# M55M1 register map
File version: 1.0
Registers are 32-bit, read-write, reset 0x0 unless marked. A register's access mark holds for its fields unless they carry their own. Offsets are from the block's base; [hi:lo] are bit positions; {n}, {i} and the like mark numbered series; 'fields as' and 'values as' point back to an identical list.

## CLK (part 2 of 2) — CLK Register Map
Base 0x40001000
0x25C CLK_I3CCTL — I3C Clock Enable Control Register
  [0] I3C0CKEN — I3Cx Clock Enable Bit. Note: This bit is not retained when D0 power is turned off.
    0=I3Cx clock Disabled; 1=I3Cx clock Enabled
0x260 CLK_KDFCTL — KDF Clock Enable Control Register
  [0] KDF0CKEN — KDFx Clock Enable Bit. Note: This bit is not retained when D0 power is turned off.
    0=KDFx clock Disabled; 1=KDFx clock Enabled
0x264 CLK_KPICTL — KPI Clock Enable Control Register
  [0] KPI0CKEN — KPIx Clock Enable Bit. Note: This bit is not retained when D0 power is turned off.
    0=KPIx clock Disabled; 1=KPIx clock Enabled
0x268 CLK_KSCTL — KS Clock Enable Control Register
  [0] KS0CKEN — KSx Clock Enable Bit. Note: This bit is not retained when D0 power is turned off.
    0=KSx clock Disabled; 1=KSx clock Enabled
0x26C CLK_LPADCCTL — Low Power ADC Clock Enable Control Register
  [0] LPADC0CKEN — LPADCx Clock Enable Bit. Note: This bit is not retained when D0 power is turned off.
    0=LPADCx clock Disabled; 1=LPADCx clock Enabled
0x270 CLK_LPPDMACTL — Low Power PDMA Clock Enable Control Register
  [0] LPPDMA0CKEN — LPPDMAx Clock Enable Bit. Note: This bit is not retained when D0 power is turned off.
    0=LPPDMAx clock Disabled; 1=LPPDMAx clock Enabled
0x274 CLK_LPGPIOCTL — Low Power GPIO Clock Enable Control Register
  [0] LPGPIO0CKEN — LPGPIOx Clock Enable Bit. Note: This bit is not retained when D0 power is turned off.
    0=LPGPIOx clock Disabled; 1=LPGPIOx clock Enabled
0x278 CLK_LPI2CCTL — Low Power I2C Clock Enable Control Register
  [0] LPI2C0CKEN — LPI2Cx Clock Enable Bit. Note: This bit is not retained when D0 power is turned off.
    0=LPI2Cx clock Disabled; 1=LPI2Cx clock Enabled
0x27C CLK_LPSPICTL — Low Power SPI Clock Enable Control Register
  [0] LPSPI0CKEN — LPSPIx Clock Enable Bit. Note: This bit is not retained when D0 power is turned off.
    0=LPSPIx clock Disabled; 1=LPSPIx clock Enabled
0x280 CLK_LPSRAMCTL — Low Power SRAM Clock Enable Control Register
  [0] LPSRAM0CKEN — LPSRAMx Clock Enable Bit. Note: This bit is not retained when D0 power is turned off.
    0=LPSRAMx clock Disabled; 1=LPSRAMx clock Enabled
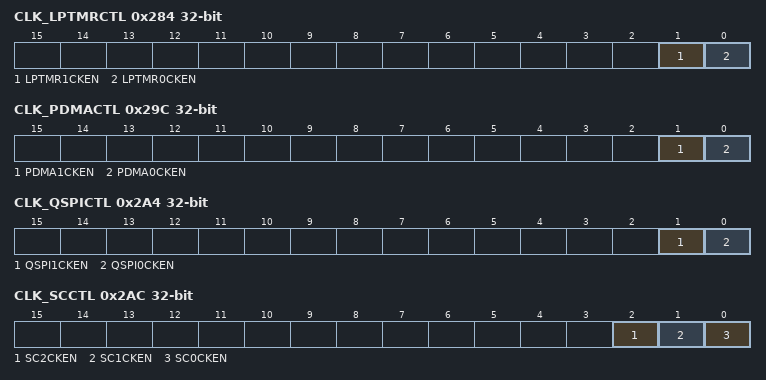
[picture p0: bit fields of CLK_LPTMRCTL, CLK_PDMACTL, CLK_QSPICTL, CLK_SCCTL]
0x284 CLK_LPTMRCTL — Low Power Timer Clock Enable Control Register
  [1] LPTMR1CKEN — LPTMRx Clock Enable Bit. Note: This bit is not retained when D0 power is turned off.
    0=LPTMRx clock Disabled; 1=LPTMRx clock Enabled
  [0] LPTMR0CKEN — LPTMRx Clock Enable Bit. Note: This bit is not retained when D0 power is turned off.
    0=LPTMRx clock Disabled; 1=LPTMRx clock Enabled
0x288 CLK_LPUARTCTL — Low Power UART Clock Enable Control Register
  [0] LPUART0CKEN — LPUARTx Clock Enable Bit. Note: This bit is not retained when D0 power is turned off.
    0=LPUARTx clock Disabled; 1=LPUARTx clock Enabled
0x28C CLK_NPUCTL — NPU Clock Enable Control Register
  [0] NPU0CKEN — NPUx Clock Enable Bit. Note: This bit is not retained when D0 power is turned off.
    0=NPUx clock Disabled; 1=NPUx clock Enabled
0x294 CLK_OTFCCTL — OTFC Clock Enable Control Register
  [0] OTFC0CKEN — OTFCx Clock Enable Bit. Note: This bit is not retained when D0 power is turned off.
    0=OTFCx clock Disabled; 1=OTFCx clock Enabled
0x298 CLK_OTGCTL — OTG Clock Enable Control Register
  [0] OTG0CKEN — OTGx Clock Enable Bit. Note: This bit is not retained when D0 power is turned off.
    0=OTGx clock Disabled; 1=OTGx clock Enabled
0x29C CLK_PDMACTL — PDMA Clock Enable Control Register
  [1] PDMA1CKEN — PDMAx Clock Enable Bit. Note: This bit is not retained when D0 power is turned off.
    0=PDMAx clock Disabled; 1=PDMAx clock Enabled
  [0] PDMA0CKEN — PDMAx Clock Enable Bit. Note: This bit is not retained when D0 power is turned off.
    0=PDMAx clock Disabled; 1=PDMAx clock Enabled
0x2A0 CLK_PSIOCTL — PSIO Clock Enable Control Register
  [0] PSIO0CKEN — PSIOx Clock Enable Bit. Note: This bit is not retained when D0 power is turned off.
    0=PSIOx clock Disabled; 1=PSIOx clock Enabled
0x2A4 CLK_QSPICTL — QSPI Clock Enable Control Register
  [1] QSPI1CKEN — QSPIx Clock Enable Bit. Note: This bit is not retained when D0 power is turned off.
    0=QSPIx clock Disabled; 1=QSPIx clock Enabled
  [0] QSPI0CKEN — QSPIx Clock Enable Bit. Note: This bit is not retained when D0 power is turned off.
    0=QSPIx clock Disabled; 1=QSPIx clock Enabled
0x2A8 CLK_RTCCTL — RTC Clock Enable Control Register
  [0] RTC0CKEN — RTCx Clock Enable Bit. Note: This bit is not retained when D0 power is turned off.
    0=RTCx clock Disabled; 1=RTCx clock Enabled
0x2AC CLK_SCCTL — SC Clock Enable Control Register
  [all] fields
    0=SCx clock Disabled; 1=SCx clock Enabled
  [2] SC2CKEN — SCx Clock Enable Bit. Note: This bit is not retained when D0 power is turned off.
  [1] SC1CKEN — SCx Clock Enable Bit. Note: This bit is not retained when D0 power is turned off.
  [0] SC0CKEN — SCx Clock Enable Bit. Note: This bit is not retained when D0 power is turned off.
0x2B0 CLK_SCUCTL reset 0x1 — SCU Clock Enable Control Register
  [0] SCU0CKEN — SCUx Clock Enable Bit. Note: This bit is not retained when D0 power is turned off.
    0=SCUx clock Disabled; 1=SCUx clock Enabled
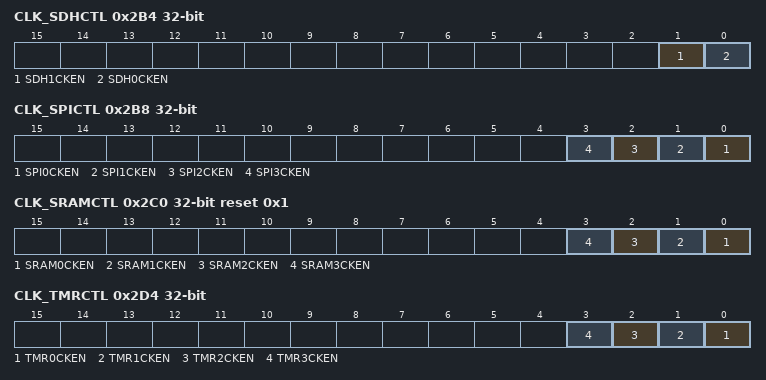
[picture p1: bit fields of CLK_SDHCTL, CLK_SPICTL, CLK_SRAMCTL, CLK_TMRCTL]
0x2B4 CLK_SDHCTL — SDH Clock Enable Control Register
  [1] SDH1CKEN — SDHx Clock Enable Bit. Note: This bit is not retained when D0 power is turned off.
    0=SDHx clock Disabled; 1=SDHx clock Enabled
  [0] SDH0CKEN — SDHx Clock Enable Bit. Note: This bit is not retained when D0 power is turned off.
    0=SDHx clock Disabled; 1=SDHx clock Enabled
0x2B8 CLK_SPICTL — SPI Clock Enable Control Register
  [all] fields
    0=SPIx clock Disabled; 1=SPIx clock Enabled
  [n] SPI{n}CKEN (n=0..3) — SPIx Clock Enable Bit. Note: This bit is not retained when D0 power is turned off.
0x2BC CLK_SPIMCTL — SPIM Clock Enable Control Register
  [0] SPIM0CKEN — SPIMx Clock Enable Bit. Note: This bit is not retained when D0 power is turned off.
    0=SPIMx clock Disabled; 1=SPIMx clock Enabled
0x2C0 CLK_SRAMCTL reset 0x1 — System SRAM Clock Enable Control Register
  [n] SRAM{n}CKEN (n=0..3) — SRAM{n} Clock Enable Bit. Note: This bit is not retained when D0 power is turned off.
    0=SRAM{n} clock Disabled; 1=SRAM{n} clock Enabled
0x2CC CLK_STCTL — System Tick Clock Enable Control Register
  [0] ST0CKEN — SYSTICKx Clock Enable Bit. Note: This bit is not retained when D0 power is turned off.
    0=SYSTICKx clock Disabled; 1=SYSTICKx clock Enabled
0x2D4 CLK_TMRCTL — Timer Clock Enable Control Register
  [all] fields
    0=TIMERx clock Disabled; 1=TIMERx clock Enabled
  [n] TMR{n}CKEN (n=0..3) — TIMERx Clock Enable Bit. Note: This bit is not retained when D0 power is turned off.
0x2D8 CLK_TRNGCTL — TRNG Clock Enable Control Register
  [0] TRNG0CKEN — TRNGx Clock Enable Bit. Note: This bit is not retained when D0 power is turned off.
    0=TRNGx clock Disabled; 1=TRNGx clock Enabled
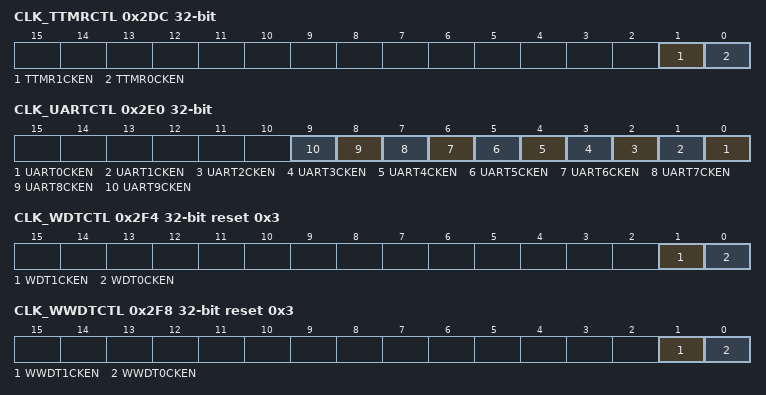
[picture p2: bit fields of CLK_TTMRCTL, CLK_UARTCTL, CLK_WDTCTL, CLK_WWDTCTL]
0x2DC CLK_TTMRCTL — Tick Timer Clock Enable Control Register
  [1] TTMR1CKEN — TTMRx Clock Enable Bit. Note: This bit is not retained when D2 power is turned off.
    0=TTMRx clock Disabled; 1=TTMRx clock Enabled
  [0] TTMR0CKEN — TTMRx Clock Enable Bit. Note: This bit is not retained when D2 power is turned off.
    0=TTMRx clock Disabled; 1=TTMRx clock Enabled
0x2E0 CLK_UARTCTL — UART Clock Enable Control Register
  [all] fields
    0=UARTx clock Disabled; 1=UARTx clock Enabled
  [n] UART{n}CKEN (n=0..9) — UARTx Clock Enable Bit. Note: This bit is not retained when D0 power is turned off.
0x2E4 CLK_USBDCTL — USBD Clock Enable Control Register
  [0] USBD0CKEN — USBDx Clock Enable Bit. Note: This bit is not retained when D0 power is turned off.
    0=USBDx clock Disabled; 1=USBDx clock Enabled
0x2E8 CLK_USBHCTL — USBH Clock Enable Control Register
  [0] USBH0CKEN — USBHx Clock Enable Bit. Note: This bit is not retained when D0 power is turned off.
    0=USBHx clock Disabled; 1=USBHx clock Enabled
0x2EC CLK_USCICTL — USCI Clock Enable Control Register
  [0] USCI0CKEN — USCIx Clock Enable Bit. Note: This bit is not retained when D0 power is turned off.
    0=USCIx clock Disabled; 1=USCIx clock Enabled
0x2F0 CLK_UTCPDCTL — UTCPD Clock Enable Control Register
  [0] UTCPD0CKEN — UTCPDx Clock Enable Bit. Note: This bit is not retained when D0 power is turned off.
    0=UTCPDx clock Disabled; 1=UTCPDx clock Enabled
0x2F4 CLK_WDTCTL reset 0x3 — WDT Clock Enable Control Register
  [1] WDT1CKEN — WDTx Clock Enable Bit. Note 2: This bit is not retained when D2 power is turned off.
    0=WDTx clock Disabled; 1=WDTx clock Enabled
  [0] WDT0CKEN — WDTx Clock Enable Bit. Note 2: This bit is not retained when D2 power is turned off.
    0=WDTx clock Disabled; 1=WDTx clock Enabled
0x2F8 CLK_WWDTCTL reset 0x3 — WWDT Clock Enable Control Register
  [1] WWDT1CKEN — WWDTx Clock Enable Bit. Note 2: This bit is not retained when D0 power is turned off.
    0=WWDTx clock Disabled; 1=WWDTx clock Enabled
  [0] WWDT0CKEN — WWDTx Clock Enable Bit. Note 2: This bit is not retained when D0 power is turned off.
    0=WWDTx clock Disabled; 1=WWDTx clock Enabled
0x400 CLK_SCLKSEL — System Clock Source Select Control Register
  [2:0] SCLKSEL — System Clock Source Selection (Write Protect). The system clock source is defined by SCLKSEL. Note: These bits are write protected. Refer to the SYS_REGLCTL register. Note: These bits are not retained when D2 power is turned off.
    0=Clock source from HIRC; 1=Clock source from MIRC; 2=Clock source from HIRC48M; 3=Clock source from HXT; 4=Clock source from APLL0
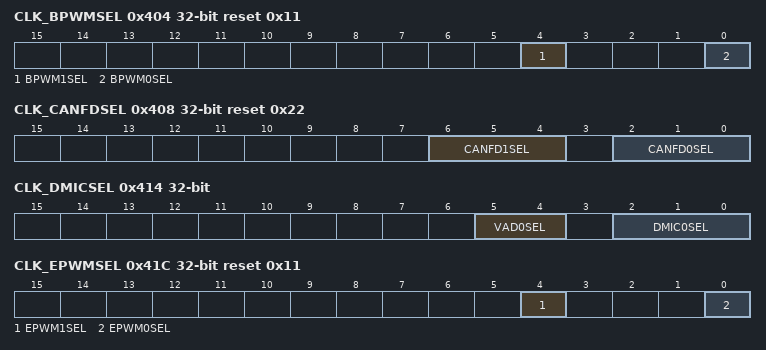
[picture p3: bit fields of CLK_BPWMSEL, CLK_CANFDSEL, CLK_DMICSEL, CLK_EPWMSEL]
0x404 CLK_BPWMSEL reset 0x11 — BPWM Clock Source Select Control Register
  [4] BPWM1SEL — BPWM1 Clock Source Selection (Write Protect). The peripheral clock source of BPWM1 is defined by BPWM1SEL. Note 0: This bit is write protected. Refer to the SYS_REGLCTL register. Note 1: This bit is not retained when D1 power is turned off.
    0=Clock source from PCLK2; 1=Clock source from HCLK0
  [0] BPWM0SEL — BPWM0 Clock Source Selection (Write Protect). The peripheral clock source of BPWM0 is defined by BPWM0SEL. Note 0: This bit is write protected. Refer to the SYS_REGLCTL register. Note 1: This bit is not retained when D1 power is turned off.
    0=Clock source from PCLK0; 1=Clock source from HCLK0
0x408 CLK_CANFDSEL reset 0x22 — CANFD Clock Source Select Control Register
  [6:4] CANFD1SEL — CANFD1 Clock Source Selection (Write Protect). The peripheral clock source of CANFD1 is defined by CANFD1SEL. Note 0: These bits are write protected. Refer to the SYS_REGLCTL register. Note 1: These bits are not retained when D1 power is turned off.
    0=Clock source from HXT; 1=Clock source from APLL0/2; 2=Clock source from HCLK0; 3=Clock source from HIRC; 4=Clock source from HIRC48M/4
  [2:0] CANFD0SEL — CANFD0 Clock Source Selection (Write Protect). The peripheral clock source of CANFD0 is defined by CANFD0SEL. Note 0: These bits are write protected. Refer to the SYS_REGLCTL register. Note 1: These bits are not retained when D1 power is turned off.
    values as CANFD1SEL
0x40C CLK_CCAPSEL reset 0x1 — CCAP Clock Source Select Control Register
  [2:0] CCAP0SEL — CCAP Sensor Clock Source Selection (Write Protect). The peripheral clock source of CCAP is defined by CCAP0SEL. Note 0: These bits are write protected. Refer to the SYS_REGLCTL register. Note 1: These bits are not retained when D2 power is turned off.
    0=Clock source from MIRC; 1=Clock source from HCLK2; 2=Clock source from HIRC; 3=Clock source from APLL0/2; 4=Clock source from HXT
0x410 CLK_CLKOSEL — Clock Output Clock Source Select Control Register
  [3:0] CLKOSEL — Clock Output Clock Source Selection (Write Protect). Note: These bits are write protected. Refer to the SYS_REGLCTL register. Note: These bits are not retained when D2 power is turned off.
    0=Clock source from SCLK; 1=Clock source from ACLK; 2=Clock source from HCLK0; 3=Clock source from HCLK1; 4=Clock source from HCLK2; 5=Clock source from APLL0/2; 6=Clock source from APLL1/2; 7=Clock source from HIRC48M; 8=Clock source from HXT; 9=Clock source from HIRC; 10=Clock source from MIRC; 11=Clock source from LXT; 12=Clock source from LIRC
0x414 CLK_DMICSEL — DMIC Clock Source Select Control Register
  [5:4] VAD0SEL — VAD Clock Source Selection (Write Protect). The peripheral clock VAD source of DIMC0 is defined by VAD0SEL. Note 0: These bits are write protected. Refer to the SYS_REGLCTL register. Note 1: These bits are not retained when D2 power is turned off.
    0=Clock source from PCLK4; 1=Clock source from MIRC; 2=Clock source from HIRC
  [2:0] DMIC0SEL — DMIC Clock Source Selection (Write Protect). The peripheral clock source of DIMC0 is defined by DMIC0SEL. Note 0: These bits are write protected. Refer to the SYS_REGLCTL register. Note 1: These bits are not retained when D2 power is turned off.
    0=Clock source from HXT; 1=Clock source from APLL1/2; 2=Clock source from MIRC; 3=Clock source from HIRC; 4=Clock source from HIRC48M; 5=Clock source from PCLK4
0x418 CLK_EADCSEL reset 0x2 — EADC Clock Source Select Control Register
  [1:0] EADC0SEL — EADC0 Clock Source Selection (Write Protect). The peripheral clock source of EADC0 is defined by EADC0SEL. Note 0: These bits are write protected. Refer to the SYS_REGLCTL register. Note 1: These bits are not retained when D1 power is turned off.
    0=Clock source from APLL1/2; 1=Clock source from APLL0/2; 2=PCLK0
0x41C CLK_EPWMSEL reset 0x11 — EPWM Clock Source Select Control Register
  [4] EPWM1SEL — EPWM1 Clock Source Selection (Write Protect). The peripheral clock source of EPWM1 is defined by EPWM1SEL. Note 0: This bit is write protected. Refer to the SYS_REGLCTL register. Note 1: This bit is not retained when D1 power is turned off.
    0=Clock source from PCLK2; 1=Clock source from HCLK0
  [0] EPWM0SEL — EPWM0 Clock Source Selection (Write Protect). The peripheral clock source of EPWM0 is defined by EPWM0SEL. Note 0: This bit is write protected. Refer to the SYS_REGLCTL register. Note 1: This bit is not retained when D1 power is turned off.
    0=Clock source from PCLK0; 1=Clock source from HCLK0
0x420 CLK_FMCSEL — FMC Clock Source Select Control Register
  [0] FMC0SEL — FMC0 Clock Source Selection (Write Protect). The peripheral clock source of FMC0 is defined by FMC0SEL. Note 0: This bit is write protected. Refer to the SYS_REGLCTL register. Note 1: This bit is not retained when D0 power is turned off.
    0=Clock source from HIRC; 1=Clock source from HIRC48M/4
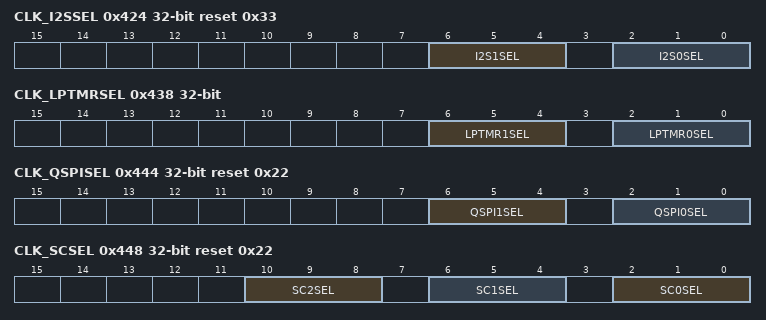
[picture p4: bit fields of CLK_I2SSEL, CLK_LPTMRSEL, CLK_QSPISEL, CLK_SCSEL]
0x424 CLK_I2SSEL reset 0x33 — I2S Clock Source Select Control Register
  [6:4] I2S1SEL — I2S1 Clock Source Selection (Write Protect). The peripheral clock source of I2S1 is defined by I2S1SEL. Note 1: These bits are write protected. Refer to the SYS_REGLCTL register. Note 2: These bits are not retained when D1 power is turned off.
    0=Clock source from HXT; 1=Clock source from APLL1/2; 2=Clock source from APLL0/2; 3=Clock source from PCLK3; 4=Clock source from HIRC; 5=Clock source from HIRC48M
  [2:0] I2S0SEL — I2S0 Clock Source Selection (Write Protect). The peripheral clock source of I2S0 is defined by I2S0SEL. Note 1: These bits are write protected. Refer to the SYS_REGLCTL register. Note 2: These bits are not retained when D1 power is turned off.
    0=Clock source from HXT; 1=Clock source from APLL1/2; 2=Clock source from APLL0/2; 3=Clock source from PCLK1; 4=Clock source from HIRC; 5=Clock source from HIRC48M
0x428 CLK_I3CSEL — I3C Clock Source Select Control Register
  [0] I3C0SEL — I3C0 Clock Source Selection (Write Protect). The peripheral clock source of I3C0 is defined by I3C0SEL. Note 1: This bit is write protected. Refer to the SYS_REGLCTL register. Note 2: This bit is not retained when D1 power is turned off.
    0=Clock source from HCLK0; 1=Clock source from APLL1/2
0x42C CLK_KPISEL — KPI Clock Source Select Control Register
  [1:0] KPI0SEL — KPI0 Clock Source Selection (Write Protect). The peripheral clock source of KPI0 is defined by KPI0SEL. Note 1: These bits are write protected. Refer to the SYS_REGLCTL register. Note 2: These bits are not retained when D1 power is turned off.
    0=Clock source from HIRC48M/4; 1=Clock source from HIRC; 2=Clock source from LIRC; 3=Clock source from HXT
0x430 CLK_LPADCSEL — Low Power ADC Clock Source Select Control Register
  [1:0] LPADC0SEL — LPADC0 Clock Source Selection (Write Protect). The peripheral clock source of LPADC0 is defined by LPADC0SEL. Note 1: These bits are write protected. Refer to the SYS_REGLCTL register. Note 2: These bits are not retained when D2 power is turned off.
    0=Clock source from PCLK4; 1=Clock source from LXT; 2=Clock source from MIRC; 3=Clock source from HIRC
0x434 CLK_LPSPISEL — Low Power SPI Clock Source Select Control Register
  [1:0] LPSPI0SEL — LPSPI0 Clock Source Selection (Write Protect). The peripheral clock source of LPSPI0 is defined by LPSPI0SEL. Note 1: These bits are write protected. Refer to the SYS_REGLCTL register. Note 2: These bits are not retained when D2 power is turned off.
    values as CLK_DMICSEL.VAD0SEL
0x438 CLK_LPTMRSEL — Low Power Timer Clock Source Select Control Register
  [6:4] LPTMR1SEL — LPTMR1 Clock Source Selection (Write Protect). The peripheral clock source of LPTMR1 is defined by LPTMR1SEL. Note 1: These bits are write protected. Refer to the SYS_REGLCTL register. Note 2: These bits are not retained when D2 power is turned off.
    0=Clock source from PCLK4; 1=Clock source from LXT; 2=Clock source from LIRC; 3=Clock source from MIRC; 4=Clock source from HIRC; 5=Clock source from external clock TM1 pin
  [2:0] LPTMR0SEL — LPTMR0 Clock Source Selection (Write Protect). The peripheral clock source of LPTMR0 is defined by LPTMR0SEL. Note 1: These bits are write protected. Refer to the SYS_REGLCTL register. Note 2: These bits are not retained when D2 power is turned off.
    0=Clock source from PCLK4; 1=Clock source from LXT; 2=Clock source from LIRC; 3=Clock source from MIRC; 4=Clock source from HIRC; 5=Clock source from external clock TM0 pin
0x43C CLK_LPUARTSEL — Low Power UART Clock Source Select Control Register
  [1:0] LPUART0SEL — LPUART0 Clock Source Selection (Write Protect). The peripheral clock source of LPUART0 is defined by LPUART0SEL. Note 1: These bits are write protected. Refer to the SYS_REGLCTL register. Note 2: These bits are not retained when D2 power is turned off.
    values as CLK_LPADCSEL.LPADC0SEL
0x440 CLK_PSIOSEL reset 0x5 — PSIO Clock Source Select Control Register
  [2:0] PSIO0SEL — PSIO0 Clock Source Selection (Write Protect). The peripheral clock source of PSIO0 is defined by PSIO0SEL. Note 1: These bits are write protected. Refer to the SYS_REGLCTL register. Note 2: These bits are not retained when D1 power is turned off.
    0=Clock source from LXT; 1=Clock source from HXT; 2=Clock source from LIRC; 3=Clock source from HIRC; 4=Clock source from HIRC48M/4; 5=Clock source from PCLK1; 6=Clock source from APLL0/2
0x444 CLK_QSPISEL reset 0x22 — QSPI Clock Source Select Control Register
  [6:4] QSPI1SEL — QSPI1 Clock Source Selection (Write Protect). The peripheral clock source of QSPI1 is defined by QSPI1SEL. Note 1: These bits are write protected. Refer to the SYS_REGLCTL register. Note 2: These bits are not retained when D1 power is turned off.
    0=Clock source from HXT; 1=Clock source from APLL0/2; 2=Clock source from PCLK2; 3=Clock source from HIRC; 4=Clock source from HIRC48M/4
  [2:0] QSPI0SEL — QSPI0 Clock Source Selection (Write Protect). The peripheral clock source of QSPI0 is defined by QSPI0SEL. Note 1: These bits are write protected. Refer to the SYS_REGLCTL register. Note 2: These bits are not retained when D1 power is turned off.
    0=Clock source from HXT; 1=Clock source from APLL0/2; 2=Clock source from PCLK0; 3=Clock source from HIRC; 4=Clock source from HIRC48M/4
0x448 CLK_SCSEL reset 0x22 — SC Clock Source Select Control Register
  [10:8] SC2SEL — SC2 Clock Source Selection (Write Protect). The peripheral clock source of SC2 is defined by SC2SEL. Note 1: These bits are write protected. Refer to the SYS_REGLCTL register. Note 2: These bits are not retained when D1 power is turned off.
    0=Clock source from HXT; 1=Clock source from APLL0/2; 2=Clock source from PCLK1; 3=Clock source from HIRC; 4=Clock source from HIRC48M/4
  [6:4] SC1SEL — SC1 Clock Source Selection (Write Protect). The peripheral clock source of SC1 is defined by SC1SEL. Note 1: These bits are write protected. Refer to the SYS_REGLCTL register. Note 2: These bits are not retained when D1 power is turned off.
    0=Clock source from HXT; 1=Clock source from APLL0/2; 2=Clock source from PCLK3; 3=Clock source from HIRC; 4=Clock source from HIRC48M/4
  [2:0] SC0SEL — SC0 Clock Source Selection (Write Protect). The peripheral clock source of SC0 is defined by SC0SEL. Note 1: These bits are write protected. Refer to the SYS_REGLCTL register. Note 2: These bits are not retained when D1 power is turned off.
    values as SC2SEL
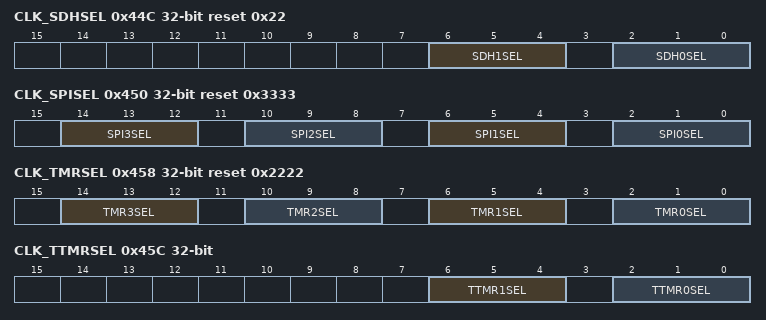
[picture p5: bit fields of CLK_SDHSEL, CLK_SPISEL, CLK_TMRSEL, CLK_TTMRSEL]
0x44C CLK_SDHSEL reset 0x22 — SDH Clock Source Select Control Register
  [6:4] SDH1SEL — SDH1 Clock Source Selection (Write Protect). The peripheral clock source of SDH1 is defined by SDH1SEL. Note 1: These bits are write protected. Refer to the SYS_REGLCTL register. Note 2: These bits are not retained when D1 power is turned off.
    0=Clock source from HXT; 1=Clock source from APLL1/2; 2=Clock source from HCLK0; 3=Clock source from HIRC; 4=Clock source from HIRC48M/4
  [2:0] SDH0SEL — SDH0 Clock Source Selection (Write Protect). The peripheral clock source of SDH0 is defined by SDH0SEL. Note 1: These bits are write protected. Refer to the SYS_REGLCTL register. Note 2: These bits are not retained when D1 power is turned off.
    values as SDH1SEL
0x450 CLK_SPISEL reset 0x3333 — SPI Clock Source Select Control Register
  [14:12] SPI3SEL — SPI3 Clock Source Selection (Write Protect). The peripheral clock source of SPI3 is defined by SPI3SEL. Note 1: These bits are write protected. Refer to the SYS_REGLCTL register. Note 2: These bits are not retained when D1 power is turned off.
    0=Clock source from HXT; 1=Clock source from APLL1/2; 2=Clock source from APLL0/2; 3=Clock source from PCLK2; 4=Clock source from HIRC; 5=Clock source from HIRC48M
  [10:8] SPI2SEL — SPI2 Clock Source Selection (Write Protect). The peripheral clock source of SPI2 is defined by SPI2SEL. Note 1: These bits are write protected. Refer to the SYS_REGLCTL register. Note 2: These bits are not retained when D1 power is turned off.
    0=Clock source from HXT; 1=Clock source from APLL1/2; 2=Clock source from APLL0/2; 3=Clock source from PCLK0; 4=Clock source from HIRC; 5=Clock source from HIRC48M
  [6:4] SPI1SEL — SPI1 Clock Source Selection (Write Protect). The peripheral clock source of SPI1 is defined by SPI1SEL. Note 1: These bits are write protected. Refer to the SYS_REGLCTL register. Note 2: These bits are not retained when D1 power is turned off.
    values as SPI3SEL
  [2:0] SPI0SEL — SPI0 Clock Source Selection (Write Protect). The peripheral clock source of SPI0 is defined by SPI0SEL. Note 1: These bits are write protected. Refer to the SYS_REGLCTL register. Note 2: These bits are not retained when D1 power is turned off.
    values as SPI2SEL
0x454 CLK_STSEL reset 0x2 — System Tick Clock Source Select Control Register
  [1:0] ST0SEL — Cortex-M55 SysTick 0 Clock Source Selection (Write Protect). Note 2: These bits are write protected. Refer to the SYS_REGLCTL register. Note 3: These bits are not retained when D0 power is turned off.
    0=Clock source from HXT; 1=Clock source from HXT/2; 2=Clock source from ACLK/2; 3=Clock source from HIRC/2
0x458 CLK_TMRSEL reset 0x2222 — Timer Clock Source Select Control Register
  [14:12] TMR3SEL — Timer 3 Clock Source Selection (Write Protect). The peripheral clock source of TMR3 is defined by TMR3SEL. Note 1: These bits are write protected. Refer to the SYS_REGLCTL register. Note 2: These bits are not retained when D1 power is turned off.
    0=Clock source from HXT; 1=Clock source from LXT; 2=Clock source from PCLK3; 3=Clock source from external clock TM3 pin; 4=Clock source from LIRC; 5=Clock source from HIRC; 6=Clock source from HIRC48M/4
  [10:8] TMR2SEL — Timer 2 Clock Source Selection (Write Protect). The peripheral clock source of TMR2 is defined by TMR2SEL. Note 1: These bits are write protected. Refer to the SYS_REGLCTL register. Note 2: These bits are not retained when D1 power is turned off.
    0=Clock source from HXT; 1=Clock source from LXT; 2=Clock source from PCLK3; 3=Clock source from external clock TM2 pin; 4=Clock source from LIRC; 5=Clock source from HIRC; 6=Clock source from HIRC48M/4
  [6:4] TMR1SEL — Timer 1 Clock Source Selection (Write Protect). The peripheral clock source of TMR1 is defined by TMR1SEL. Note 1: These bits are write protected. Refer to the SYS_REGLCTL register. Note 2: These bits are not retained when D1 power is turned off.
    0=Clock source from HXT; 1=Clock source from LXT; 2=Clock source from PCLK1; 3=Clock source from external clock TM1 pin; 4=Clock source from LIRC; 5=Clock source from HIRC; 6=Clock source from HIRC48M/4
  [2:0] TMR0SEL — Timer 0 Clock Source Selection (Write Protect). The peripheral clock source of TMR0 is defined by TMR0SEL. Note 1: These bits are write protected. Refer to the SYS_REGLCTL register. Note 2: These bits are not retained when D1 power is turned off.
    0=Clock source from HXT; 1=Clock source from LXT; 2=Clock source from PCLK1; 3=Clock source from external clock TM0 pin; 4=Clock source from LIRC; 5=Clock source from HIRC; 6=Clock source from HIRC48M/4
0x45C CLK_TTMRSEL — Tick Timer Clock Source Select Control Register
  [6:4] TTMR1SEL — Tick Timer 1 Clock Source Selection (Write Protect). The peripheral clock source of TTMR1 is defined by TTMR1SEL. Note 1: These bits are write protected. Refer to the SYS_REGLCTL register. Note 2: These bits are not retained when D2 power is turned off.
    0=Clock source from PCLK4; 1=Clock source from LXT; 2=Clock source from LIRC; 3=Clock source from MIRC; 4=Clock source from HIRC
  [2:0] TTMR0SEL — Tick Timer 0 Clock Source Selection (Write Protect). The peripheral clock source of TTMR0 is defined by TTMR0SEL. Note 1: These bits are write protected. Refer to the SYS_REGLCTL register. Note 2: These bits are not retained when D2 power is turned off.
    values as TTMR1SEL
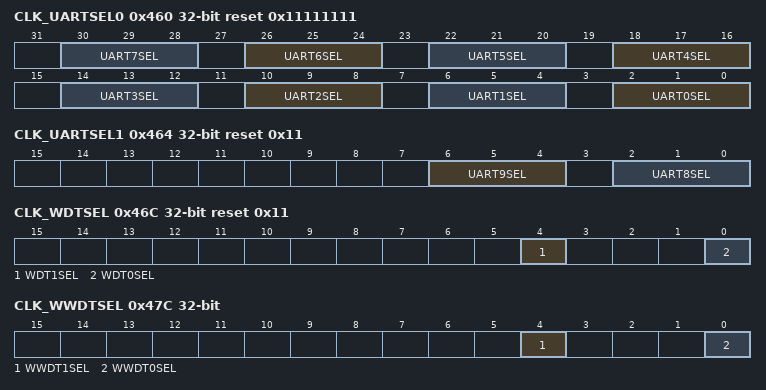
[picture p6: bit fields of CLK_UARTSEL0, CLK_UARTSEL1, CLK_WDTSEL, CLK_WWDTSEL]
0x460 CLK_UARTSEL0 reset 0x11111111 — UART Clock Source Select Control Register 0
  [all] fields
    0=Clock source from HXT; 1=Clock source from HIRC; 2=Clock source from LXT; 3=Clock source from APLL0/2; 4=Clock source from HIRC48M
  [4n+2:4n] UART{n}SEL (n=0..7) — UART {n} Clock Source Selection (Write Protect). The peripheral clock source of UART{n} is defined by UART{n}SEL. Note 1: These bits are write protected. Refer to the SYS_REGLCTL register. Note 2: These bits are not retained when D1 power is turned off.
0x464 CLK_UARTSEL1 reset 0x11 — UART Clock Source Select Control Register 1
  [6:4] UART9SEL — UART 9 Clock Source Selection (Write Protect). The peripheral clock source of UART9 is defined by UART9SEL. Note 1: These bits are write protected. Refer to the SYS_REGLCTL register. Note 2: These bits are not retained when D1 power is turned off.
    values as the fields of CLK_UARTSEL0
  [2:0] UART8SEL — UART 8 Clock Source Selection (Write Protect). The peripheral clock source of UART8 is defined by UART8SEL. Note 1: These bits are write protected. Refer to the SYS_REGLCTL register. Note 2: These bits are not retained when D1 power is turned off.
    values as the fields of CLK_UARTSEL0
0x468 CLK_USBSEL reset 0x1 — USB Clock Source Select Control Register
  [0] USBSEL — USB Clock Source Selection (Write Protect). The peripheral clock source of USBH, USBD and OTG is defined by USBSEL. Note 1: These bits are write protected. Refer to the SYS_REGLCTL register. Note 2: These bits are not retained when D1 power is turned off.
    0=Clock source from HIRC48M; 1=Clock source from APLL1/2
0x46C CLK_WDTSEL reset 0x11 — WDT Clock Source Select Control Register
  [4] WDT1SEL — WDT1 Clock Source Selection (Write Protect). The peripheral clock source of WDT1 is defined by WDT1SEL. Note 1: These bits are write protected. Refer to the SYS_REGLCTL register. Note 2: These bits are not retained when D2 power is turned off.
    0=Clock source from LXT; 1=Clock source from LIRC
  [0] WDT0SEL — WDT0 Clock Source Selection (Write Protect). The peripheral clock source of WDT0 is defined by WDT0SEL. Note 1: These bits are write protected. Refer to the SYS_REGLCTL register. Note 2: These bits are not retained when D2 power is turned off.
    0=Clock source from LXT; 1=Clock source from LIRC
0x474 CLK_DLLSEL — DLL Clock Source Select Control Register
  [0] DLL0SEL — DLL0 Clock Source Selection (Write Protect). Note 1: This bit is write protected. Refer to the SYS_REGLCTL register. Note 2: This bit is not retained when D0 power is turned off.
    0=Clock source from APLL0; 1=Clock source from APLL1
0x47C CLK_WWDTSEL — WWDT Clock Source Select Control Register
  [4] WWDT1SEL — WWDT1 Clock Source Selection (Write Protect). Note 1: This bit is write protected. Refer to the SYS_REGLCTL register. Note 2: This bit is not retained when D0 power is turned off.
    0=Clock source from LIRC; 1=Clock source from LXT
  [0] WWDT0SEL — WWDT0 Clock Source Selection (Write Protect). Note 1: This bit is write protected. Refer to the SYS_REGLCTL register. Note 2: This bit is not retained when D0 power is turned off.
    0=Clock source from LIRC; 1=Clock source from LXT
0x500 CLK_SCLKDIV — SCLK Clock Divider Control Register
  [3:0] SCLKDIV — SCLK Clock Divide Number from SCLK Clock Source. Note: These bits are not retained when D2 power is turned off.
0x508 CLK_HCLKDIV — HCLK Clock Divider Control Register
  [11:8] HCLK2DIV — HCLK2 Clock Divide Number from HCLK2 Clock Source. Note: These bits are not retained when D2 power is turned off.
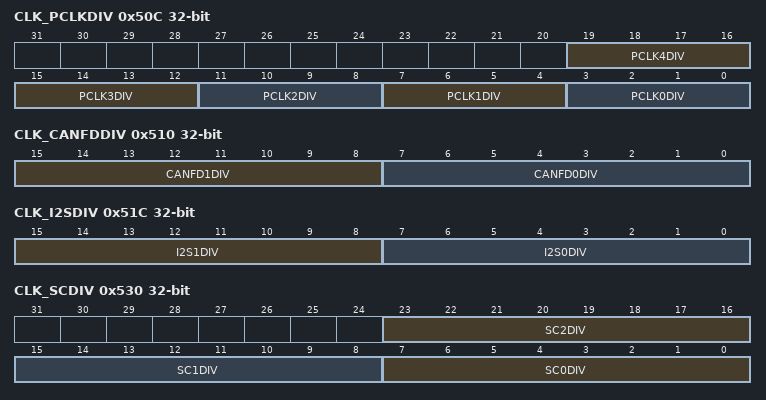
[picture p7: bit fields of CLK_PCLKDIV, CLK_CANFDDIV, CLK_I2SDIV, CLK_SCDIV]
0x50C CLK_PCLKDIV — PCLK Clock Divider Control Register
  [19:16] PCLK4DIV — PCLK4 Clock Divide Number from PCLK4 Clock Source. Note: These bits are not retained when D2 power is turned off.
  [4n+3:4n] PCLK{n}DIV (n=0..3) — PCLK{n} Clock Divide Number from PCLK{n} Clock Source. Note: These bits are not retained when D1 power is turned off.
0x510 CLK_CANFDDIV — CANFD Clock Divider Control Register
  [15:8] CANFD1DIV — CANFD1 Clock Divide Number from CANFD1 Clock Source. Note: These bits are not retained when D1 power is turned off.
  [7:0] CANFD0DIV — CANFD0 Clock Divide Number from CANFD0 Clock Source. Note: These bits are not retained when D1 power is turned off.
0x514 CLK_DMICDIV — DMIC Clock Divider Control Register
  [7:0] DMIC0DIV — DMIC0 Clock Divide Number from DMIC0 Clock Source. Note: These bits are not retained when D2 power is turned off.
0x518 CLK_EADCDIV — EADC Clock Divider Control Register
  [7:0] EADC0DIV — EADC0 Clock Divide Number from EADC0 Clock Source. Note: These bits are not retained when D1 power is turned off.
0x51C CLK_I2SDIV — I2S Clock Divider Control Register
  [15:8] I2S1DIV — I2S1 Clock Divide Number from I2S1 Clock Source. Note: These bits are not retained when D1 power is turned off.
  [7:0] I2S0DIV — I2S0 Clock Divide Number from I2S0 Clock Source. Note: These bits are not retained when D1 power is turned off.
0x520 CLK_KPIDIV — KPI Clock Divider Control Register
  [7:0] KPI0DIV — KPI0 Clock Divide Number from KPI0 Clock Source. Note: These bits are not retained when D1 power is turned off.
0x524 CLK_LPADCDIV — Low Power ADC Clock Divider Control Register
  [7:0] LPADC0DIV — LPADC0 Clock Divide Number from LPADC0 Clock Source. Note: These bits are not retained when D2 power is turned off.
0x528 CLK_LPUARTDIV — Low Power UART Clock Divider Control Register
  [3:0] LPUART0DIV — LPUART0 Clock Divide Number from LPUART0 Clock Source. Note: These bits are not retained when D2 power is turned off.
0x52C CLK_PSIODIV — PSIO Clock Divider Control Register
  [7:0] PSIO0DIV — PSIO0 Clock Divide Number from PSIO0 Clock Source. Note: These bits are not retained when D1 power is turned off.
0x530 CLK_SCDIV — SC Clock Divider Control Register
  [23:16] SC2DIV — SC2 Clock Divide Number from SC2 Clock Source. Note: These bits are not retained when D1 power is turned off.
  [15:8] SC1DIV — SC1 Clock Divide Number from SC1 Clock Source. Note: These bits are not retained when D1 power is turned off.
  [7:0] SC0DIV — SC0 Clock Divide Number from SC0 Clock Source. Note: These bits are not retained when D1 power is turned off.
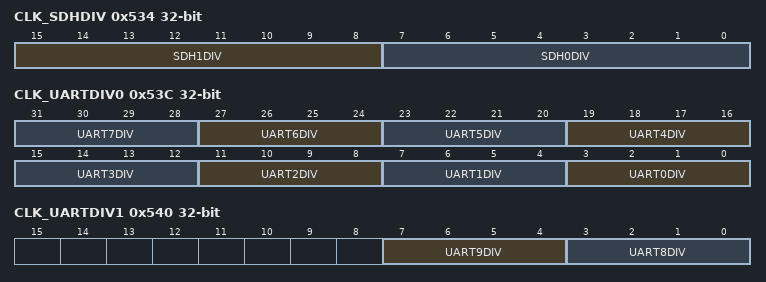
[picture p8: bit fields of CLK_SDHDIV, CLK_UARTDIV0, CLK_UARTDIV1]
0x534 CLK_SDHDIV — SDH Clock Divider Control Register
  [15:8] SDH1DIV — SDH1 Clock Divide Number from SDH1 Clock Source. Note: These bits are not retained when D1 power is turned off.
  [7:0] SDH0DIV — SDH0 Clock Divide Number from SDH0 Clock Source. Note: These bits are not retained when D1 power is turned off.
0x538 CLK_STDIV — System Tick Clock Divider Control Register
  [7:0] ST0DIV — System Tick 0 Clock Divide Number from System Tick 0 Clock Source. Note: These bits are not retained when D0 power is turned off.
0x53C CLK_UARTDIV0 — UART Clock Divider Control Register 0
  [4n+3:4n] UART{n}DIV (n=0..7) — UART{n} Clock Divide Number from UART{n} Clock Source. Note: These bits are not retained when D1 power is turned off.
0x540 CLK_UARTDIV1 — UART Clock Divider Control Register 1
  [7:4] UART9DIV — UART9 Clock Divide Number from UART9 Clock Source. Note: These bits are not retained when D1 power is turned off.
  [3:0] UART8DIV — UART8 Clock Divide Number from UART8 Clock Source. Note: These bits are not retained when D1 power is turned off.
0x544 CLK_USBDIV — USB Clock Divider Control Register
  [3:0] USBDIV — USB Clock Divide Number from USB Clock Source. Note: These bits are not retained when D1 power is turned off.
0x548 CLK_VSENSEDIV — Video Pixel Clock Divider Control Register
  [3:0] VSENSEDIV — Video Pixel Clock Divide Number from Video Pixel Clock Source. Note: These bits are not retained when D2 power is turned off.
